# MKM33ZA5 register map
Vendor: Freescale Semiconductor, Inc.; File version: 1.6
CPU: CM0PLUS r0p0, little endian, no MPU, no FPU, 0x2 interrupt priority bits, 0x0 interrupts
Registers are 32-bit, read-write, reset 0x0 unless marked. A register's access mark holds for its fields unless they carry their own. Offsets are from the block's base; [hi:lo] are bit positions; {n}, {i} and the like mark numbered series; 'fields as' and 'values as' point back to an identical list.

## RCM — Reset Control Module
Base 0x4007B000; register names take the prefix RCM_
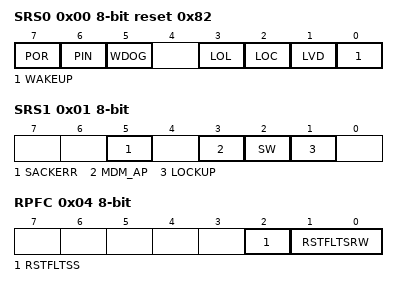
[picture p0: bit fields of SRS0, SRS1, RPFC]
0x00 SRS0 8-bit ro reset 0x82 — System Reset Status Register 0
  [7] POR — Power-On Reset
    0=Reset not caused by POR; 1=Reset caused by POR
  [6] PIN — External Reset Pin
    0=Reset not caused by external reset pin; 1=Reset caused by external reset pin
  [5] WDOG — Watchdog
    0=Reset not caused by watchdog timeout; 1=Reset caused by watchdog timeout
  [3] LOL — Loss-of-Lock Reset
    0=Reset not caused by a loss of lock in the PLL; 1=Reset caused by a loss of lock in the PLL
  [2] LOC — Loss-of-Clock Reset
    0=Reset not caused by a loss of external clock; 1=Reset caused by a loss of external clock
  [1] LVD — Low-Voltage Detect Reset
    0=Reset not caused by LVD trip or POR; 1=Reset caused by LVD trip or POR
  [0] WAKEUP — Low Leakage Wakeup Reset
    0=Reset not caused by wakeup source; 1=Reset caused by wakeup source
0x01 SRS1 8-bit ro — System Reset Status Register 1
  [5] SACKERR — Stop Mode Acknowledge Error Reset
    0=Reset not caused by peripheral failure to acknowledge attempt to enter stop mode; 1=Reset caused by peripheral failure to acknowledge attempt to enter stop mode
  [3] MDM_AP — MDM-AP System Reset Request
    0=Reset not caused by host debugger system setting of the System Reset Request bit; 1=Reset caused by host debugger system setting of the System Reset Request bit
  [2] SW — Software
    0=Reset not caused by software setting of SYSRESETREQ bit; 1=Reset caused by software setting of SYSRESETREQ bit
  [1] LOCKUP — Core Lockup
    0=Reset not caused by core LOCKUP event; 1=Reset caused by core LOCKUP event
0x04 RPFC 8-bit — Reset Pin Filter Control register
  [2] RSTFLTSS — Reset Pin Filter Select in Stop Mode
    0=All filtering disabled; 1=LPO clock filter enabled
  [1:0] RSTFLTSRW — Reset Pin Filter Select in Run and Wait Modes
    0=All filtering disabled; 1=Bus clock filter enabled for normal operation; 2=LPO clock filter enabled for normal operation
0x05 RPFW 8-bit — Reset Pin Filter Width register
  [4:0] RSTFLTSEL — Reset Pin Filter Bus Clock Select
    {v}=Bus clock filter count is {v+1} (v=0..31)

## LLWU — Low leakage wakeup unit
Base 0x4007C000; register names take the prefix LLWU_
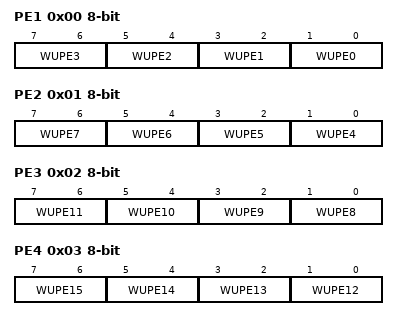
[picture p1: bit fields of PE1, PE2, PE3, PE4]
0x00 PE1 8-bit — LLWU Pin Enable 1 register
  [all] fields
    0=External input pin disabled as wakeup input; 1=External input pin enabled with rising edge detection; 2=External input pin enabled with falling edge detection; 3=External input pin enabled with any change detection
  [2n+1:2n] WUPE{n} (n=0..3) — Wakeup Pin Enable For LLWU_P{n}
0x01 PE2 8-bit — LLWU Pin Enable 2 register
  [all] fields
    values as the fields of PE1
  [2n-7:2n-8] WUPE{n} (n=4..7) — Wakeup Pin Enable For LLWU_P{n}
0x02 PE3 8-bit — LLWU Pin Enable 3 register
  [all] fields
    values as the fields of PE1
  [2n-15:2n-16] WUPE{n} (n=8..11) — Wakeup Pin Enable For LLWU_P{n}
0x03 PE4 8-bit — LLWU Pin Enable 4 register
  [all] fields
    values as the fields of PE1
  [2n-23:2n-24] WUPE{n} (n=12..15) — Wakeup Pin Enable For LLWU_P{n}
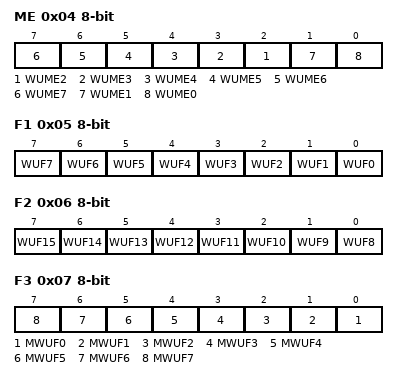
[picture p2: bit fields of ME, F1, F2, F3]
0x04 ME 8-bit — LLWU Module Enable register
  [all] fields
    0=Internal module flag not used as wakeup source; 1=Internal module flag used as wakeup source
  [n] WUME{n} (n=2..7) — Wakeup Module Enable For Module {n}
  [1] WUME1 — Wakeup Module Enable for Module 1
  [0] WUME0 — Wakeup Module Enable For Module 0
0x05 F1 8-bit — LLWU Flag 1 register
  [n] WUF{n} (n=4..7) — Wakeup Flag For LLWU_P{n}
    0=LLWU_P{n} input was not a wakeup source; 1=LLWU_P{n} input was a wakeup source
  [3] WUF3 — Wakeup Flag For LLWU_P3
    0=LLWU_P3 input was not a wake-up source; 1=LLWU_P3 input was a wake-up source
  [2] WUF2 — Wakeup Flag For LLWU_P2
    0=LLWU_P2 input was not a wakeup source; 1=LLWU_P2 input was a wakeup source
  [1] WUF1 — Wakeup Flag For LLWU_P1
    0=LLWU_P1 input was not a wakeup source; 1=LLWU_P1 input was a wakeup source
  [0] WUF0 — Wakeup Flag For LLWU_P0
    0=LLWU_P0 input was not a wakeup source; 1=LLWU_P0 input was a wakeup source
0x06 F2 8-bit — LLWU Flag 2 register
  [n-8] WUF{n} (n=8..15) — Wakeup Flag For LLWU_P{n}
    values as F1.WUF4
0x07 F3 8-bit ro — LLWU Flag 3 register
  [n] MWUF{n} (n=0..7) — Wakeup flag For module {n}
    0=Module {n} input was not a wakeup source; 1=Module {n} input was a wakeup source
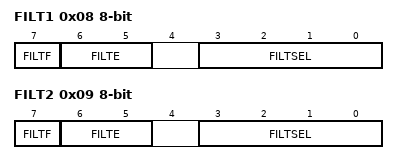
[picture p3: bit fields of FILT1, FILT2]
0x08 FILT1 8-bit — LLWU Pin Filter 1 register
  [7] FILTF — Filter Detect Flag
    0=Pin Filter 1 was not a wakeup source; 1=Pin Filter 1 was a wakeup source
  [6:5] FILTE — Digital Filter On External Pin
    0=Filter disabled; 1=Filter posedge detect enabled; 2=Filter negedge detect enabled; 3=Filter any edge detect enabled
  [3:0] FILTSEL — Filter Pin Select
    0=Select LLWU_P0 for filter; 15=Select LLWU_P15 for filter
0x09 FILT2 8-bit — LLWU Pin Filter 2 register
  [7] FILTF — Filter Detect Flag
    0=Pin Filter 2 was not a wakeup source; 1=Pin Filter 2 was a wakeup source
  [6:5] FILTE — Digital Filter On External Pin
    values as FILT1.FILTE
  [3:0] FILTSEL — Filter Pin Select
    0=Select LLWU_P0 for filter; 15=Select LLWU_P15 for filter
